# QSPI0_QSPI0 register map
Vendor: Texas Instruments
Peripheral module from a debugger description file (folder AM263).
Registers are 32-bit, access per field, reset 0x0 unless marked. A register's access mark holds for its fields unless they carry their own. Offsets are as the file gives them; lines under a group give offsets from that group; [hi:lo] are bit positions; {n}, {i} and the like mark numbered series; 'fields as' and 'values as' point back to an identical list; <NAME> marks a mode.

## QSPI0_QSPI0
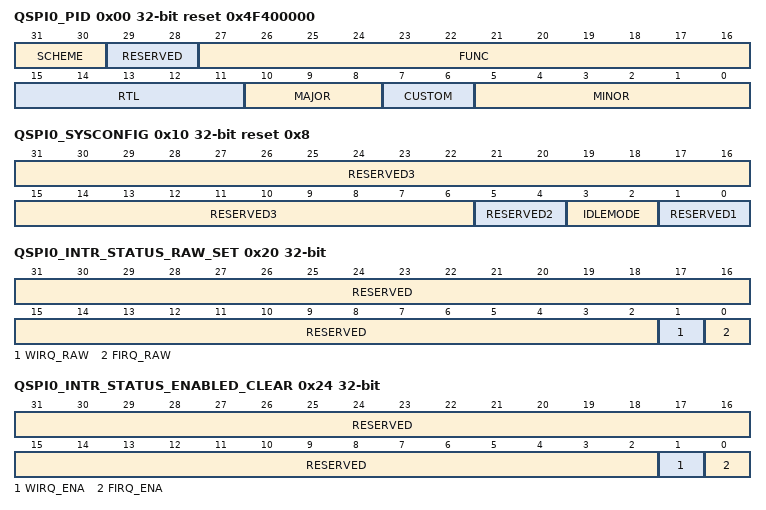
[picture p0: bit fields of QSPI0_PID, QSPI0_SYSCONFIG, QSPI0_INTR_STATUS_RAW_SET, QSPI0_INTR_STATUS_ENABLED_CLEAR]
0x00 QSPI0_PID ro reset 0x4F400000
  [31:30] SCHEME — The scheme of the register used. This indicates the PDR3.5 Method
  [29:28] RESERVED — Always read as 0
  [27:16] FUNC — The function of the module being used
  [15:11] RTL — RTL Release Version The PDR release number of this IP
  [10:8] MAJOR — Major Release Number
  [7:6] CUSTOM — Custom IP
  [5:0] MINOR — Minor Release Number
{0x0+4i} QSPI0_MSS_QSPI_RESERVED{i} access not given reset not defined (i=1..3)
0x10 QSPI0_SYSCONFIG reset 0x8
  [31:6] RESERVED3 ro — Always read as 0
  [5:4] RESERVED2 ro — Always read as 0
  [3:2] IDLEMODE rw — Configuration of the local target state management mode. By definition, target can handle read/write transaction as long as it is out of IDLE state0x0 : Force-idle mode: local target's idle state follows (acknowledges) the system's idle requests unconditionally, i.e. regardless of the IP module's internal requirements. Backup mode, for debug only0x1 : No-idle mode: local target never enters idle state. Backup mode, for debug only0x2 : Smart-idle mode: local target's idle state eventually follows (acknowledges) the system's idle requests, depending on the IP module's internal requirements. IP module shall not generate (IRQ- or DMA-request-related) wakeup events0x3 : Smart-idle wakeup-capable mode: local target's idle state eventually follows (acknowledges) the system's idle requests, depending on the IP module's internal requirements. IP module may generate (IRQ- or DMA-request-related) wakeup events when in idle state.Mode is only relevant if the appropriate IP module 'swakeup' output(s) is (are) implemented
  [1:0] RESERVED1 ro — Always read as 0
{0x4+4i} QSPI0_MSS_QSPI_RESERVED{i} access not given reset not defined (i=4..6)
0x20 QSPI0_INTR_STATUS_RAW_SET
  [31:2] RESERVED ro — Always read as 0
  [1] WIRQ_RAW rw — Word Interrupt Status Read indicates raw status0 = inactive1 = activeWriting 1 will set statusWriting 0 has no effect
  [0] FIRQ_RAW rw — Frame Interrupt StatusRead indicates raw status0 = inactive1 = activeWriting 1 will set statusWriting 0 has no effect
0x24 QSPI0_INTR_STATUS_ENABLED_CLEAR
  [31:2] RESERVED ro — Always read as 0
  [1] WIRQ_ENA rw — Word Interrupt Enabled StatusRead indicates enabled status0 = inactive1 = activeWriting 1 will clear interruptWriting 0 has no effect
  [0] FIRQ_ENA rw — Frame Interrupt Enabled StatusRead indicates enabled status0 = inactive1 = activeWriting 1 will clear interruptWriting 0 has no effect
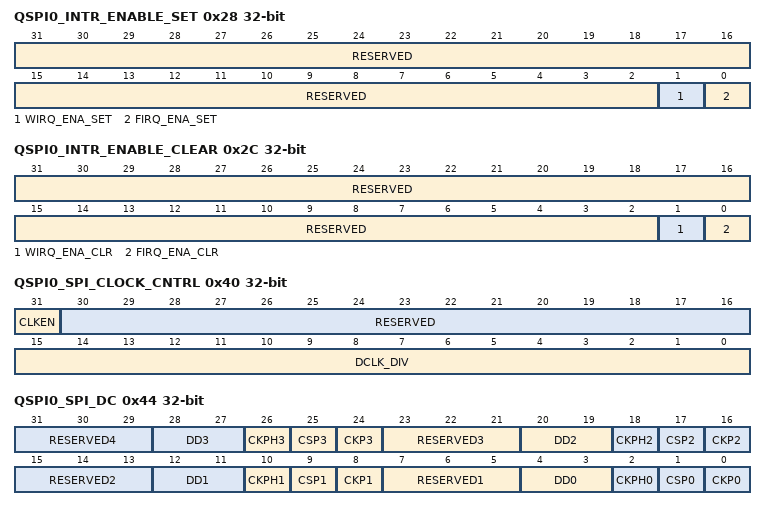
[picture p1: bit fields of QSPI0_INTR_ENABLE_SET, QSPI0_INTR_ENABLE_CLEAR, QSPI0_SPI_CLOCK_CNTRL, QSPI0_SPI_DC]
0x28 QSPI0_INTR_ENABLE_SET
  [31:2] RESERVED ro — Always read as 0
  [1] WIRQ_ENA_SET rw — Word Interrupt Enable/SetRead indicates interrupt enable0 = disabled1 = enabledWriting 1 will set interrupt enabledWriting 0 has no effect
  [0] FIRQ_ENA_SET rw — Frame Interrupt Enable/SetRead indicates interrupt enable0 = disabled1 = enabledWriting 1 will set interrupt enabledWriting 0 has no effect
0x2C QSPI0_INTR_ENABLE_CLEAR
  [31:2] RESERVED ro — Always read as 0
  [1] WIRQ_ENA_CLR rw — Word Interrupt Enable/ClearRead indicates interrupt enable0 = disabled1 = enabledWriting 1 will clear interrupt enabledWriting 0 has no effect
  [0] FIRQ_ENA_CLR rw — Frame Interrupt Enable/ClearRead indicates interrupt enable0 = disabled1 = enabledWriting 1 will clear interrupt enabledWriting 0 has no effect
0x30 QSPI0_INTC_EOI rw
  [31:0] EOI_VECTOR — Number associated with the ipgenericirq for intr output. There are 1 interrupt outputsWrite 0x0 : Write to intr IP GenericAny other write value is ignored.
{0x18+4i} QSPI0_MSS_QSPI_RESERVED{i} access not given reset not defined (i=7..9)
0x40 QSPI0_SPI_CLOCK_CNTRL
  [31] CLKEN rw — Clock Enable. 0- Data clock is turned off1- Data clock is enabled
  [30:16] RESERVED ro — Always read as 0
  [15:0] DCLK_DIV rw — Serial data clock divide by ratio
0x44 QSPI0_SPI_DC
  [8n-1:8n-3] RESERVED{n} ro (n=1..4) — Always read as 0
  [8n+4:8n+3] DD{n} rw (n=0..3) — Data delay for chip select {100n:03}- Data is output on the same cycle as the CS_N goes active01- Data is output 1 DCLK cycle after the CS_N goes active 10- Data is output 2 DCLK cycles after the CS_N goes active11- Data is output 3 DCLK cycles after the CS_N goes active
  [26] CKPH3 rw — Clock phase for chip select 3 If CKP0 = 0 0- Data shifted out on falling edge; input on rising edge 1- Data shifted out on rising edge; input on falling edgeIf CKP0 = 1 1- Data shifted out on falling edge; input on rising edge 0- Data shifted out on rising edge; input on falling edge
  [8n+1] CSP{n} rw (n=0..3) — Chip select polarity for chip select {10n:02}- Active low1- Active high
  [8n] CKP{n} rw (n=0..3) — Clock polarity for chip select {10n:02}- When data is not being transferred, SCK = 01- When data is not being transferred, SCK = 1
  [18] CKPH2 rw — Clock phase for chip select 2. If CKP0 = 0 0- Data shifted out on falling edge; input on rising edge 1- Data shifted out on rising edge; input on falling edgeIf CKP0 = 1 1- Data shifted out on falling edge; input on rising edge 0- Data shifted out on rising edge; input on falling edge
  [10] CKPH1 rw — Clock phase for chip select 1. If CKP0 = 0 0- Data shifted out on falling edge; input on rising edge 1- Data shifted out on rising edge; input on falling edgeIf CKP0 = 1 1- Data shifted out on falling edge; input on rising edge 0- Data shifted out on rising edge; input on falling edge
  [2] CKPH0 rw — Clock phase for chip select 0. If CKP0 = 0 0- Data shifted out on falling edge; input on rising edge 1- Data shifted out on rising edge; input on falling edgeIf CKP0 = 1 1- Data shifted out on falling edge; input on rising edge 0- Data shifted out on rising edge; input on falling edge
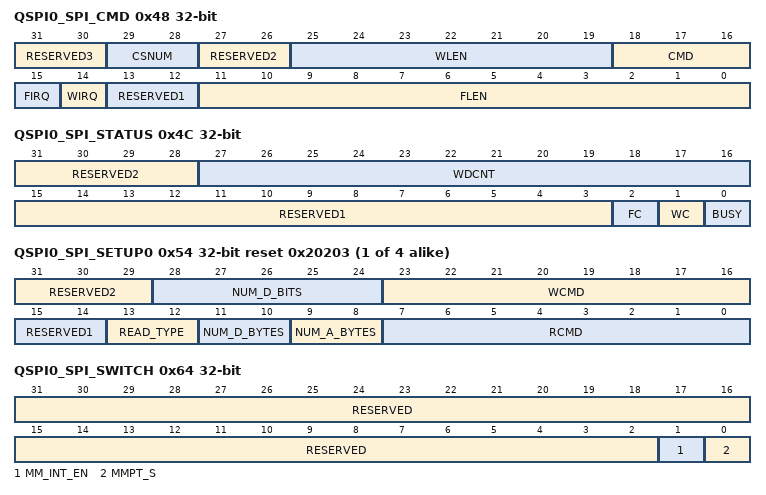
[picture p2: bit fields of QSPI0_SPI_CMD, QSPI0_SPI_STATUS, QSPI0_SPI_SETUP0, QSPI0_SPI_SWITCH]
0x48 QSPI0_SPI_CMD
  [31:30] RESERVED3 ro — Always read as 0
  [29:28] CSNUM rw — Device select. Sets the active chip select for the transfer00- Chip Select 0 active01- Chip Select 1 active10- Chip Select 2 active11- Chip Select 3 active
  [27:26] RESERVED2 ro — Always read as 0
  [25:19] WLEN rw — Word length. Sets the size of the individual transfers from 1 ? 128 bits0- 1 bit1- 2 bits?127 ? 128 bits
  [18:16] CMD rw — Transfer command000- Reserved001- 4 pin Read Single 010- 4 pin Write Single011- 4 pin Read Dual100 ? Reserved101 ? 3 pin Read Single110 ? 3 pin Write Single 111 ? 6 pin Read Quad
  [15] FIRQ rw — Frame count interrupt enable
  [14] WIRQ rw — Word count interrupt enable
  [13:12] RESERVED1 ro — Always read as 0
  [11:0] FLEN rw — Frame Length0- 1 word1- 2 words?4095 ? 4096 words
0x4C QSPI0_SPI_STATUS ro
  [31:28] RESERVED2 — Always read as 0
  [27:16] WDCNT — Word count. This field will reflect the 1-4096 words transferred
  [15:3] RESERVED1 — Always read as 0
  [2] FC — Frame complete. This bit is set after all of the requested words have been transmitted.0- Transfer is not complete1- Transfer is completeThis bit is reset when the SPI Status Register is read
  [1] WC — Word complete. This bit is set after each word transfer is completed.0- Word transfer is not complete1- Word transfer is completeThis bit is reset when the SPI Status Register is read
  [0] BUSY — Busy bit. Active transfer in progress. This bit is only set during an active word transfer. Between words, the bit will clear to signal that it is ok to read/write the data registers.0- Idle1- Busy
0x50 QSPI0_SPI_DATA rw
  [31:0] DATA — Data register for read and write operations
{0x54+4i} QSPI0_SPI_SETUP{i} reset 0x20203 (i=0..3)
  [31:29] RESERVED2 ro — Always read as 0
  [28:24] NUM_D_BITS rw — Number of dummy bits to use if NUM_D_BYTES = 0
  [23:16] WCMD rw — Write Command
  [15:14] RESERVED1 ro — Always read as 0
  [13:12] READ_TYPE rw — Determines if the read command is a single, dual or quad read mode command00 ? Normal read (all data input on spi_din)01 ? Dual read (odd bytes input on spi_din; even on spi_dout)10 ? Normal read (all data input on spi_din)11 ? Quad read (uses spi_qdin0/1)
  [11:10] NUM_D_BYTES rw — Number of dummy bytes to be used for fast read. 0 = use the value in NUM_D_BITS1 = use 8 bits; 2 = use 16 bits; 3 = use 24 bits
  [9:8] NUM_A_BYTES rw — Number of address bytes to be sent. 0 = 1 byte; 1 = 2 bytes; 2 = 3 bytes; 3 = 4 bytes
  [7:0] RCMD rw — Read Command
0x64 QSPI0_SPI_SWITCH
  [31:2] RESERVED ro — Always read as 0
  [1] MM_INT_EN rw — Memory Mapped mode interrupt enable.0 ? Interrupts are disabled during memory mapped operations1 ? Word Count interrupt is enabled for memory mapped operations
  [0] MMPT_S rw — MMPT select. If 0 (default) config port has is selected to control config of core SPI module. If 1, Memory Mapped Protocol Translator is selected to control config port of core SPI module.
{0x64+4i} QSPI0_SPI_DATA{i} rw (i=1..3)
  [31:0] DATA — Data register for read and write operations
